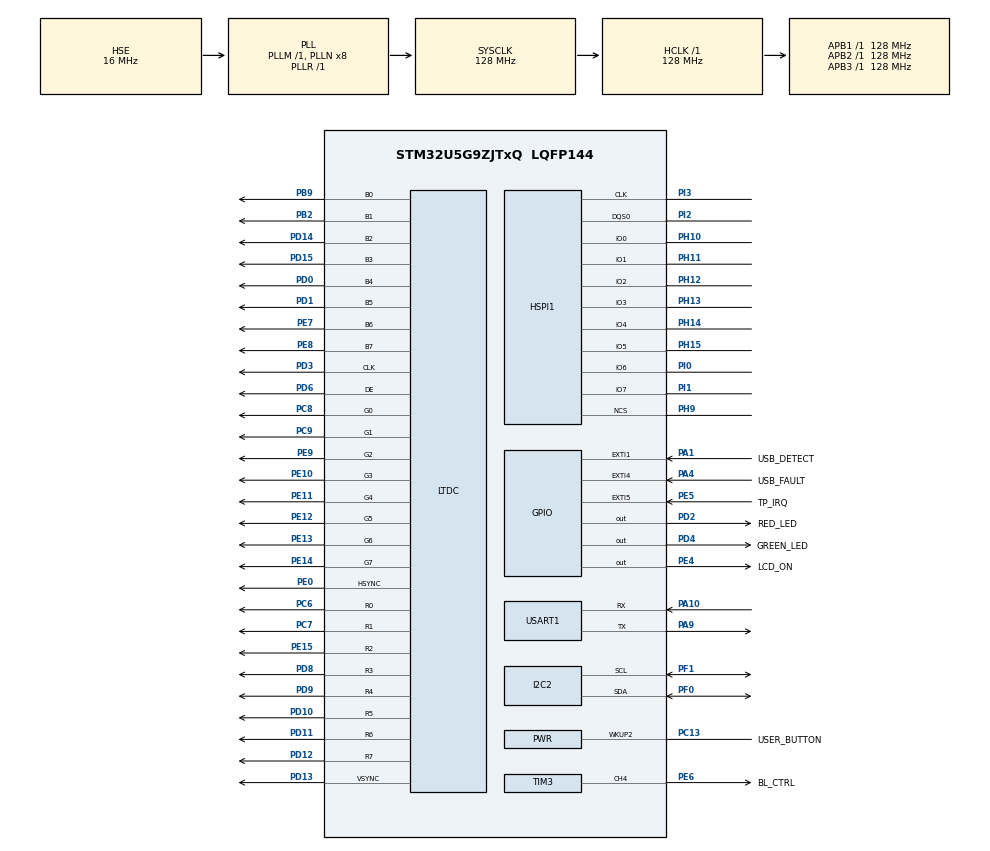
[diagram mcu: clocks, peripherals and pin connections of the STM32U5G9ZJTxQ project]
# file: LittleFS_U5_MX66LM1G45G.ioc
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CORTEX_M33_NS.userName=CORTEX_M33
DMA2D.ColorMode=DMA2D_OUTPUT_RGB888
DMA2D.Mode=DMA2D_M2M
HSPI1.ChipSelectBoundary=HAL_XSPI_BONDARYOF_NONE
HSPI1.ChipSelectHighTimeCycle=2
HSPI1.FifoThresholdByte=1
HSPI1.MemorySize=HAL_XSPI_SIZE_1GB
HSPI1.MemoryType=HAL_XSPI_MEMTYPE_MACRONIX
I2C2.Timing=0x20A0C4DF
LTDC.ActiveH=480
LTDC.ActiveW=800
LTDC.Alpha_L0=255
LTDC.BlendingFactor1_L0=LTDC_BLENDING_FACTOR1_PAxCA
LTDC.BlendingFactor2_L0=LTDC_BLENDING_FACTOR2_PAxCA
LTDC.HBP=8
LTDC.HFP=8
LTDC.HSync=4
LTDC.Layers=0
LTDC.PCPolarity=LTDC_PCPOLARITY_IPC
LTDC.PixelFormat_L0=LTDC_PIXEL_FORMAT_RGB888
LTDC.VBP=8
LTDC.VFP=8
LTDC.WindowX1_L0=800
LTDC.WindowY1_L0=480
Mcu.Family=STM32U5
Mcu.Name=STM32U5G9ZJTxQ
Mcu.Package=LQFP144
NVIC.EXTI1_IRQn=true\:0\:0\:false\:false\:true\:true\:true\:true
NVIC.EXTI4_IRQn=true\:0\:0\:false\:false\:true\:true\:true\:true
NVIC.EXTI5_IRQn=true\:0\:0\:false\:false\:true\:true\:true\:true
NVIC.I2C2_ER_IRQn=true\:0\:0\:false\:false\:true\:true\:true\:false
NVIC.I2C2_EV_IRQn=true\:0\:0\:false\:false\:true\:true\:true\:true
NVIC.LTDC_IRQn=true\:0\:0\:false\:false\:true\:true\:true\:true
NVIC.PriorityGroup=NVIC_PRIORITYGROUP_4
NVIC.USART1_IRQn=true\:0\:0\:false\:false\:true\:true\:true\:true
PA1.GPIO_Label=USB_DETECT
PA1.GPIO_ModeDefaultEXTI=GPIO_MODE_IT_RISING_FALLING
PA1.Signal=GPXTI1
PA10.Mode=Asynchronous
PA10.Signal=USART1_RX
PA11.Signal=USB_OTG_HS_DM
PA12.Signal=USB_OTG_HS_DP
PA13\ (JTMS/SWDIO).Mode=Trace_Asynchronous_SW
PA13\ (JTMS/SWDIO).Signal=DEBUG_JTMS-SWDIO
PA14\ (JTCK/SWCLK).Mode=Trace_Asynchronous_SW
PA14\ (JTCK/SWCLK).Signal=DEBUG_JTCK-SWCLK
PA4.GPIO_Label=USB_FAULT
PA4.GPIO_ModeDefaultEXTI=GPIO_MODE_IT_FALLING
PA4.GPIO_PuPd=GPIO_PULLUP
PA4.Signal=GPXTI4
PA9.Mode=Asynchronous
PA9.Signal=USART1_TX
PB2.Mode=RGB888
PB2.Signal=LTDC_B1
PB3\ (JTDO/TRACESWO).Mode=Trace_Asynchronous_SW
PB3\ (JTDO/TRACESWO).Signal=DEBUG_JTDO-SWO
PB9.Mode=RGB888
PB9.Signal=LTDC_B0
PC13.GPIO_Label=USER_BUTTON
PC13.Mode=WakeUp2
PC13.Signal=PWR_WKUP2
PC14-OSC32_IN\ (PC14).Mode=LSE-External-Oscillator
PC14-OSC32_IN\ (PC14).Signal=RCC_OSC32_IN
PC15-OSC32_OUT\ (PC15).Mode=LSE-External-Oscillator
PC15-OSC32_OUT\ (PC15).Signal=RCC_OSC32_OUT
PC6.Mode=RGB888
PC6.Signal=LTDC_R0
PC7.Mode=RGB888
PC7.Signal=LTDC_R1
PC8.Mode=RGB888
PC8.Signal=LTDC_G0
PC9.Mode=RGB888
PC9.Signal=LTDC_G1
PD0.Mode=RGB888
PD0.Signal=LTDC_B4
PD1.Mode=RGB888
PD1.Signal=LTDC_B5
PD10.Mode=RGB888
PD10.Signal=LTDC_R5
PD11.Mode=RGB888
PD11.Signal=LTDC_R6
PD12.Mode=RGB888
PD12.Signal=LTDC_R7
PD13.Mode=RGB888
PD13.Signal=LTDC_VSYNC
PD14.Mode=RGB888
PD14.Signal=LTDC_B2
PD15.Mode=RGB888
PD15.Signal=LTDC_B3
PD2.GPIO_Label=RED_LED
PD2.Signal=GPIO_Output
PD3.Mode=RGB888
PD3.Signal=LTDC_CLK
PD4.GPIO_Label=GREEN_LED
PD4.Signal=GPIO_Output
PD6.Mode=RGB888
PD6.Signal=LTDC_DE
PD8.Mode=RGB888
PD8.Signal=LTDC_R3
PD9.Mode=RGB888
PD9.Signal=LTDC_R4
PE0.Mode=RGB888
PE0.Signal=LTDC_HSYNC
PE10.Mode=RGB888
PE10.Signal=LTDC_G3
PE11.Mode=RGB888
PE11.Signal=LTDC_G4
PE12.Mode=RGB888
PE12.Signal=LTDC_G5
PE13.Mode=RGB888
PE13.Signal=LTDC_G6
PE14.Mode=RGB888
PE14.Signal=LTDC_G7
PE15.Mode=RGB888
PE15.Signal=LTDC_R2
PE4.GPIO_Label=LCD_ON
PE4.PinState=GPIO_PIN_SET
PE4.Signal=GPIO_Output
PE5.GPIO_Label=TP_IRQ
PE5.Signal=GPXTI5
PE6.GPIO_Label=BL_CTRL
PE6.Signal=S_TIM3_CH4
PE7.Mode=RGB888
PE7.Signal=LTDC_B6
PE8.Mode=RGB888
PE8.Signal=LTDC_B7
PE9.Mode=RGB888
PE9.Signal=LTDC_G2
PF0.Mode=I2C
PF0.Signal=I2C2_SDA
PF1.Mode=I2C
PF1.Signal=I2C2_SCL
PH0-OSC_IN\ (PH0).Mode=HSE-External-Oscillator
PH0-OSC_IN\ (PH0).Signal=RCC_OSC_IN
PH1-OSC_OUT\ (PH1).Mode=HSE-External-Oscillator
PH1-OSC_OUT\ (PH1).Signal=RCC_OSC_OUT
PH10.Mode=octo_mode
PH10.Signal=HSPI1_IO0
PH11.Mode=octo_mode
PH11.Signal=HSPI1_IO1
PH12.Mode=octo_mode
PH12.Signal=HSPI1_IO2
PH13.Mode=octo_mode
PH13.Signal=HSPI1_IO3
PH14.Mode=octo_mode
PH14.Signal=HSPI1_IO4
PH15.Mode=octo_mode
PH15.Signal=HSPI1_IO5
PH9.Mode=octo_mode
PH9.Signal=HSPI1_NCS
PI0.Mode=octo_mode
PI0.Signal=HSPI1_IO6
PI1.Mode=octo_mode
PI1.Signal=HSPI1_IO7
PI2.Mode=octo_mode
PI2.Signal=HSPI1_DQS0
PI3.Mode=octo_mode
PI3.Signal=HSPI1_CLK
PWR.PowerMode=PWR_SMPS_SUPPLY
ProjectManager.HeapSize=0x200
ProjectManager.StackSize=0x400
ProjectManager.TargetToolchain=STM32CubeIDE
RCC.ADCFreq_Value=16000000
RCC.AHBFreq_Value=128000000
RCC.APB1Freq_Value=128000000
RCC.APB1TimFreq_Value=128000000
RCC.APB2Freq_Value=128000000
RCC.APB2TimFreq_Value=128000000
RCC.APB3Freq_Value=128000000
RCC.CortexFreq_Value=128000000
RCC.EPOD_VALUE=16000000
RCC.HCLKFreq_Value=128000000
RCC.HSE_VALUE=16000000
RCC.HSI48_VALUE=48000000
RCC.HSI_VALUE=16000000
RCC.HSPICLockSelection=RCC_HSPICLKSOURCE_PLL2
RCC.LSIDIV_VALUE=32000
RCC.LTDCCLockSelection=RCC_LTDCCLKSOURCE_PLL3
RCC.MSIClockRange=RCC_MSIRANGE_0
RCC.MSI_VALUE=48000000
RCC.PLL1P=8
RCC.PLL1R=1
RCC.PLL2FRACN=0
RCC.PLL2N=25
RCC.PLL2Q=3
RCC.PLL2R=4
RCC.PLL2Source=RCC_PLLSOURCE_HSE
RCC.PLL3FRACN=0
RCC.PLL3M=4
RCC.PLL3N=50
RCC.PLL3R=8
RCC.PLL3Source=RCC_PLLSOURCE_HSE
RCC.PLLFRACN=0
RCC.PLLN=8
RCC.PLLSourceVirtual=RCC_PLLSOURCE_HSE
RCC.RTCClockSelection=RCC_RTCCLKSOURCE_LSE
RCC.SYSCLKFreq_VALUE=128000000
RCC.SYSCLKSource=RCC_SYSCLKSOURCE_PLLCLK
RCC.VCOOutputFreq_Value=128000000
SH.S_TIM3_CH4.0=TIM3_CH4,PWM Generation4 CH4
TIM3.Channel-PWM\ Generation4\ CH4=TIM_CHANNEL_4
TIM3.OC4Preload_PWM=DISABLE
TIM3.PeriodNoDither=100
TIM3.Prescaler=160
TIM3.PulseNoDither_4=75
USART1.VirtualMode-Asynchronous=VM_ASYNC
VP_DMA2D_VS_DMA2D.Mode=DMA2D_Activate
VP_ICACHE_VS_ICACHE.Mode=DirectMappedCache
VP_LPBAMQUEUE_VS_QUEUE.Mode=QUEUEMODE
VP_LPBAM_VS_SIG1.Mode=SmartRun
VP_LPBAM_VS_SIG4.Mode=LPDMA1
VP_MEMORYMAP_VS_MEMORYMAP.Mode=CurAppReg
VP_PWR_VS_LPOM.Mode=PowerOptimisation
VP_PWR_VS_SECSignals.Mode=Security/Privilege
VP_RTC_VS_RTC_Activate.Mode=RTC_Enabled
board=STM32U5G9J-DK2

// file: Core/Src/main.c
/* USER CODE BEGIN Header */
/**
  ******************************************************************************
  * @file           : main.c
  * @brief          : Main program body
  ******************************************************************************
  * @attention
  *
  * Copyright (c) 2024 STMicroelectronics.
  * All rights reserved.
  *
  * This software is licensed under terms that can be found in the LICENSE file
  * in the root directory of this software component.
  * If no LICENSE file comes with this software, it is provided AS-IS.
  *
  ******************************************************************************
  */
/* USER CODE END Header */
#include "main.h"
#include "dma2d.h"
#include "hspi.h"
#include "i2c.h"
#include "icache.h"
#include "ltdc.h"
#include "memorymap.h"
#include "rtc.h"
#include "tim.h"
#include "usart.h"
#include "gpio.h"

/* USER CODE BEGIN Includes */
#include "littlefs_test.h"
/* USER CODE END Includes */

void SystemClock_Config(void);
static void SystemPower_Config(void);

/* USER CODE BEGIN 0 */
#ifdef __GNUC__
#define PUTCHAR_PROTOTYPE int __io_putchar(int ch)
#else
  #define PUTCHAR_PROTOTYPE int fputc(int ch, FILE *f)
#endif // _GNUC_
PUTCHAR_PROTOTYPE
{
	HAL_UART_Transmit(&huart1, (uint8_t *)&ch, 1,10);
	return ch;
}
/* USER CODE END 0 */

int main(void)
{

  /* MCU Configuration--------------------------------------------------------*/

  /* Reset of all peripherals, Initializes the Flash interface and the Systick. */
  HAL_Init();

  /* Configure the System Power */
  SystemPower_Config();

  /* Configure the system clock */
  SystemClock_Config();

  /* Initialize all configured peripherals */
  MX_GPIO_Init();
  MX_DMA2D_Init();
  MX_HSPI1_Init();
  MX_I2C2_Init();
  MX_ICACHE_Init();
  MX_LTDC_Init();
  MX_RTC_Init();
  MX_TIM3_Init();
  MX_USART1_UART_Init();
  /* USER CODE BEGIN 2 */
  printf("\r\n\r\nLittleFS STM32U5G9J-DK2 MX66LM1G45G rev 1.0\r\n");
  littlefs_test(MX66UW1G45G_TEST_SPI_MODE);
//  littlefs_test(MX66UW1G45G_TEST_OPI_STR_MODE);
//  littlefs_test(MX66UW1G45G_TEST_OPI_DTR_MODE);
  /* USER CODE END 2 */

  /* Infinite loop */
  while (1)
  {

  }
}

void SystemClock_Config(void)
{
  RCC_OscInitTypeDef RCC_OscInitStruct = {0};
  RCC_ClkInitTypeDef RCC_ClkInitStruct = {0};

  /** Configure the main internal regulator output voltage
  */
  if (HAL_PWREx_ControlVoltageScaling(PWR_REGULATOR_VOLTAGE_SCALE1) != HAL_OK)
  {
    Error_Handler();
  }

  /** Configure LSE Drive Capability
  */
  HAL_PWR_EnableBkUpAccess();
  __HAL_RCC_LSEDRIVE_CONFIG(RCC_LSEDRIVE_LOW);

  /** Initializes the CPU, AHB and APB buses clocks
  */
  RCC_OscInitStruct.OscillatorType = RCC_OSCILLATORTYPE_HSE|RCC_OSCILLATORTYPE_LSE;
  RCC_OscInitStruct.HSEState = RCC_HSE_ON;
  RCC_OscInitStruct.LSEState = RCC_LSE_ON;
  RCC_OscInitStruct.PLL.PLLState = RCC_PLL_ON;
  RCC_OscInitStruct.PLL.PLLSource = RCC_PLLSOURCE_HSE;
  RCC_OscInitStruct.PLL.PLLMBOOST = RCC_PLLMBOOST_DIV1;
  RCC_OscInitStruct.PLL.PLLM = 1;
  RCC_OscInitStruct.PLL.PLLN = 8;
  RCC_OscInitStruct.PLL.PLLP = 8;
  RCC_OscInitStruct.PLL.PLLQ = 2;
  RCC_OscInitStruct.PLL.PLLR = 1;
  RCC_OscInitStruct.PLL.PLLRGE = RCC_PLLVCIRANGE_1;
  RCC_OscInitStruct.PLL.PLLFRACN = 0;
  if (HAL_RCC_OscConfig(&RCC_OscInitStruct) != HAL_OK)
  {
    Error_Handler();
  }

  /** Initializes the CPU, AHB and APB buses clocks
  */
  RCC_ClkInitStruct.ClockType = RCC_CLOCKTYPE_HCLK|RCC_CLOCKTYPE_SYSCLK
                              |RCC_CLOCKTYPE_PCLK1|RCC_CLOCKTYPE_PCLK2
                              |RCC_CLOCKTYPE_PCLK3;
  RCC_ClkInitStruct.SYSCLKSource = RCC_SYSCLKSOURCE_PLLCLK;
  RCC_ClkInitStruct.AHBCLKDivider = RCC_SYSCLK_DIV1;
  RCC_ClkInitStruct.APB1CLKDivider = RCC_HCLK_DIV1;
  RCC_ClkInitStruct.APB2CLKDivider = RCC_HCLK_DIV1;
  RCC_ClkInitStruct.APB3CLKDivider = RCC_HCLK_DIV1;

  if (HAL_RCC_ClockConfig(&RCC_ClkInitStruct, FLASH_LATENCY_3) != HAL_OK)
  {
    Error_Handler();
  }
}

/**
  * @brief Power Configuration
  * @retval None
  */
static void SystemPower_Config(void)
{

  /*
   * Switch to SMPS regulator instead of LDO
   */
  if (HAL_PWREx_ConfigSupply(PWR_SMPS_SUPPLY) != HAL_OK)
  {
    Error_Handler();
  }
}

void Error_Handler(void)
{
  __disable_irq();
  while (1)
  {
  }
}
